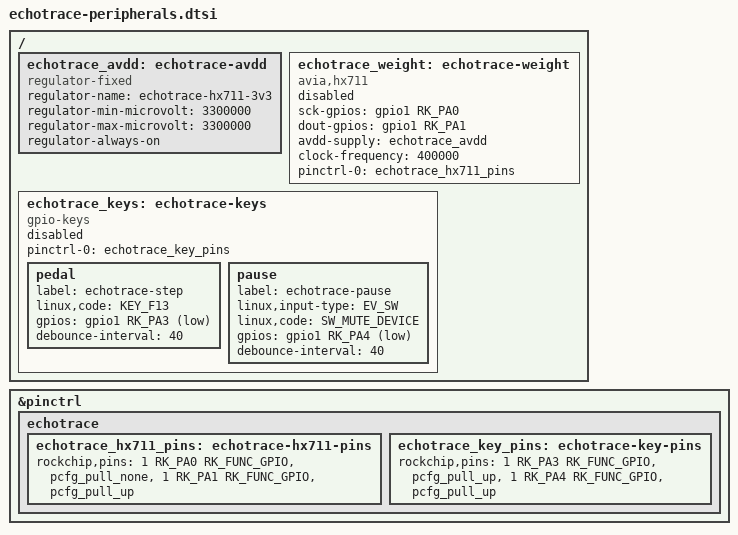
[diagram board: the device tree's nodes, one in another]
// SPDX-License-Identifier: (GPL-2.0+ OR MIT)
// Candidate wiring only. Verify PCB revision, 3.3V levels and motor disconnection.
// Include AFTER rv1106-echo-mate-ipc.dtsi. Enable nodes only after verification.
#include <dt-bindings/gpio/gpio.h>
#include <dt-bindings/input/input.h>
#include <dt-bindings/pinctrl/rockchip.h>
/ {
    echotrace_avdd: echotrace-avdd {
        compatible = "regulator-fixed";
        regulator-name = "echotrace-hx711-3v3";
        regulator-min-microvolt = <3300000>;
        regulator-max-microvolt = <3300000>;
        regulator-always-on;
    };
    echotrace_weight: echotrace-weight {
        compatible = "avia,hx711";
        sck-gpios = <&gpio1 RK_PA0 GPIO_ACTIVE_HIGH>;
        dout-gpios = <&gpio1 RK_PA1 GPIO_ACTIVE_HIGH>;
        avdd-supply = <&echotrace_avdd>;
        clock-frequency = <400000>;
        pinctrl-names = "default";
        pinctrl-0 = <&echotrace_hx711_pins>;
        status = "disabled";
    };
    echotrace_keys: echotrace-keys {
        compatible = "gpio-keys";
        pinctrl-names = "default";
        pinctrl-0 = <&echotrace_key_pins>;
        status = "disabled";
        pedal {
            label = "echotrace-step";
            linux,code = <KEY_F13>;
            gpios = <&gpio1 RK_PA3 GPIO_ACTIVE_LOW>;
            debounce-interval = <40>;
        };
        pause {
            label = "echotrace-pause";
            linux,input-type = <EV_SW>;
            linux,code = <SW_MUTE_DEVICE>;
            gpios = <&gpio1 RK_PA4 GPIO_ACTIVE_LOW>;
            debounce-interval = <40>;
        };
    };
};
&pinctrl {
    echotrace {
        echotrace_hx711_pins: echotrace-hx711-pins {
            rockchip,pins = <1 RK_PA0 RK_FUNC_GPIO &pcfg_pull_none>,
                            <1 RK_PA1 RK_FUNC_GPIO &pcfg_pull_up>;
        };
        echotrace_key_pins: echotrace-key-pins {
            rockchip,pins = <1 RK_PA3 RK_FUNC_GPIO &pcfg_pull_up>,
                            <1 RK_PA4 RK_FUNC_GPIO &pcfg_pull_up>;
        };
    };
};
